# FM33LC0XX register map
File version: 1.0
CPU: Cortex-M0 r1p0, little endian, no MPU, no FPU, 3 interrupt priority bits
Registers are 32-bit, read-write, reset 0x0 unless marked. A register's access mark holds for its fields unless they carry their own. Offsets are from the block's base; [hi:lo] are bit positions.

## VREF — VREF module information
Base 0x4001A80C
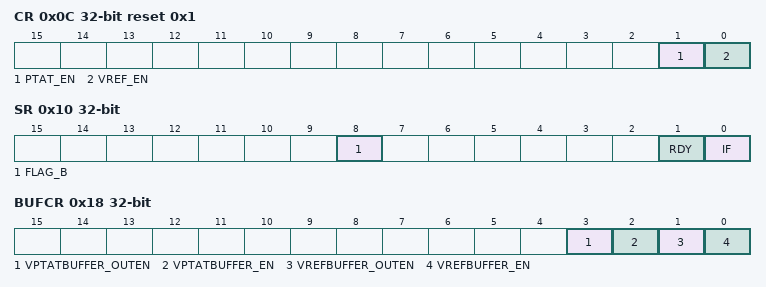
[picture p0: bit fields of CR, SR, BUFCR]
0x0C CR reset 0x1 — VREF Control Register
  [1] PTAT_EN — PTAT_EN field description
  [0] VREF_EN — VREF_EN field description
0x10 SR access per field — VREF Status Register
  [8] FLAG_B ro — FLAG_B field description
  [1] RDY ro — RDY field description
  [0] IF rw — IF field description
0x14 IER — VREF Interrupt Enable Register
  [0] IE — IE field description
0x18 BUFCR — Buffer Control Register
  [3] VPTATBUFFER_OUTEN — VPTATBUFFER_OUTEN field description
  [2] VPTATBUFFER_EN — VPTATBUFFER_EN field description
  [1] VREFBUFFER_OUTEN — VREFBUFFER_OUTEN field description
  [0] VREFBUFFER_EN — VREFBUFFER_EN field description

## DBG — DBG module information
Base 0x40000000
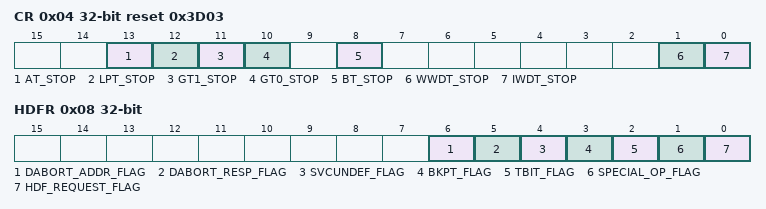
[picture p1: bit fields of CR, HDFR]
0x04 CR reset 0x3D03 — Debug Configuration Register
  [13] AT_STOP — AT_STOP field description
  [12] LPT_STOP — LPT_STOP field description
  [11] GT1_STOP — GT1_STOP field description
  [10] GT0_STOP — GT0_STOP field description
  [8] BT_STOP — BT_STOP field description
  [1] WWDT_STOP — WWDT_STOP field description
  [0] IWDT_STOP — IWDT_STOP field description
0x08 HDFR — HardFault Flag Register
  [6] DABORT_ADDR_FLAG — DABORT_ADDR_FLAG field description
  [5] DABORT_RESP_FLAG — DABORT_RESP_FLAG field description
  [4] SVCUNDEF_FLAG — SVCUNDEF_FLAG field description
  [3] BKPT_FLAG — BKPT_FLAG field description
  [2] TBIT_FLAG — TBIT_FLAG field description
  [1] SPECIAL_OP_FLAG — SPECIAL_OP_FLAG field description
  [0] HDF_REQUEST_FLAG — HDF_REQUEST_FLAG field description

## FLS — FLS module information
Base 0x40001000
0x00 RDCR — Flash Read Control Register
  [1:0] WAIT — WAIT field description
0x04 PFCR — Flash Prefetch Control Register
  [0] PRFTEN — PRFTEN field description
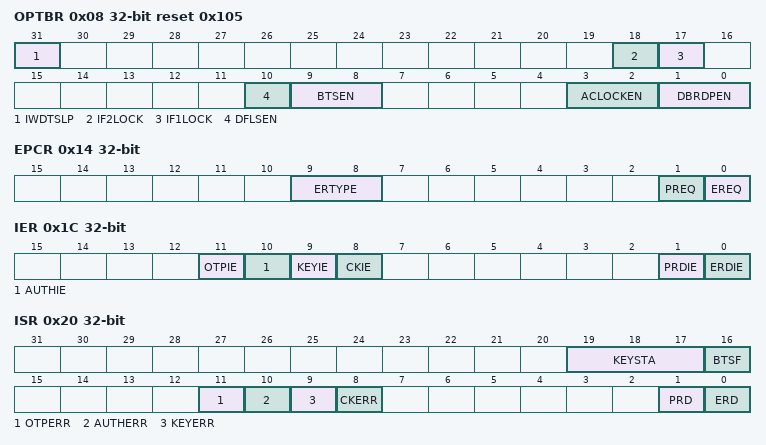
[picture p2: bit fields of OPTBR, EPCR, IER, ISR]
0x08 OPTBR ro reset 0x105 — Flash Option Bytes Register
  [31] IWDTSLP — IWDTSLP field description
  [18] IF2LOCK — IF2LOCK field description
  [17] IF1LOCK — IF1LOCK field description
  [10] DFLSEN — DFLSEN field description
  [9:8] BTSEN — BTSEN field description
  [3:2] ACLOCKEN — ACLOCKEN field description
  [1:0] DBRDPEN — DBRDPEN field description
0x0C ACLOCK1 — Flash Application Code Lock Register1
  [31:0] LOCK1 — LOCK1 field description
0x10 ACLOCK2 — Flash Application Code Lock Register2
  [31:0] LOCK2 — LOCK2 field description
0x14 EPCR — Flash Erase/Program Control Register
  [9:8] ERTYPE — ERTYPE field description
  [1] PREQ — PREQ field description
  [0] EREQ — EREQ field description
0x18 KEY wo — Flash Key Register
  [31:0] KEY — KEY field description
0x1C IER — Flash Interrupt Enable Register
  [11] OTPIE — OTPIE field description
  [10] AUTHIE — AUTHIE field description
  [9] KEYIE — KEYIE field description
  [8] CKIE — CKIE field description
  [1] PRDIE — PRDIE field description
  [0] ERDIE — ERDIE field description
0x20 ISR access per field — Flash Interrupt Status Register
  [19:17] KEYSTA ro — KEYSTA field description
  [16] BTSF ro — BTSF field description
  [11] OTPERR rw — OTPERR field description
  [10] AUTHERR rw — AUTHERR field description
  [9] KEYERR rw — KEYERR field description
  [8] CKERR rw — CKERR field description
  [1] PRD rw — PRD field description
  [0] ERD rw — ERD field description

## RMU — RMU module information
Base 0x4001A800
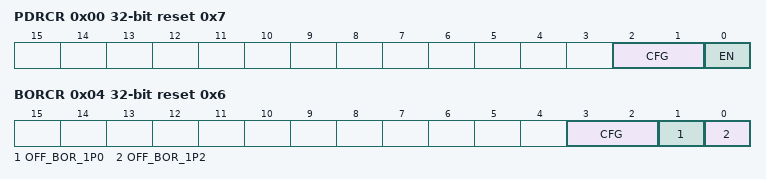
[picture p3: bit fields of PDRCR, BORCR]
0x00 PDRCR reset 0x7 — PDR Control Register
  [2:1] CFG — CFG field description
  [0] EN — EN field description
0x04 BORCR reset 0x6 — BOR Control Register
  [3:2] CFG — CFG field description
  [1] OFF_BOR_1P0 — OFF_BOR_1P0 field description
  [0] OFF_BOR_1P2 — OFF_BOR_1P2 field description

## IWDT — IWDT module information
Base 0x40011400
0x00 SERV wo — IWDT Service Register
  [31:0] SERV — SERV field description
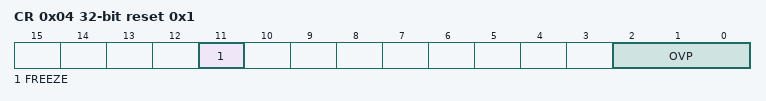
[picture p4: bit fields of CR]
0x04 CR reset 0x1 — IWDT Config Register
  [11] FREEZE — FREEZE field description
  [2:0] OVP — OVP field description
0x08 CNT ro — IWDT Counter Register
  [11:0] CNT — CNT field description
0x0C WIN — IWDT Window Register
  [11:0] WIN — WIN field description
0x10 IER — IWDT Interrupt Enable Register
  [0] IE — IE field description
0x14 ISR — IWDT Interrupt Status Register
  [0] WINF — WINF field description
